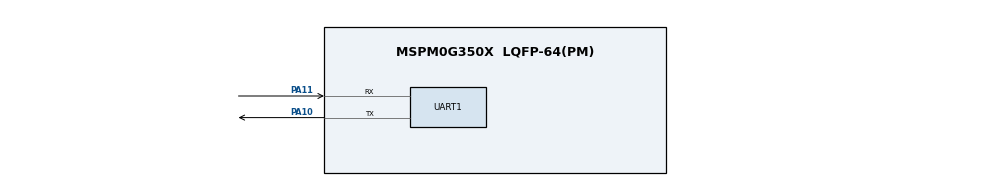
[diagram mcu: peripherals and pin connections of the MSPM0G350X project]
// @cliArgs --device "MSPM0G350X" --package "LQFP-64(PM)" --part "Default"
// @cliArgs --board /ti/boards/LP_MSPM0G3507 --rtos nortos

/**
 * Import the modules used in this configuration.
 */
const UART   = scripting.addModule("/ti/driverlib/UART", {}, false);
const UART1  = UART.addInstance();

const GPIO   = scripting.addModule("/ti/driverlib/GPIO", {}, false);
const GPIO1  = GPIO.addInstance();

const SYSCTL = scripting.addModule("/ti/driverlib/SYSCTL");

/**
 * Write custom configuration values to the imported modules.
 */

UART1.$name = "UART_0";
UART1.profile = "CONFIG_PROFILE_1";
UART1.peripheral.$assign = "UART0";
UART1.targetBaudRate = 9600;
UART1.enableInternalLoopback = false;
UART1.enableFIFO = true;
UART1.rxFifoThreshold = "DL_UART_RX_FIFO_LEVEL_1_2_FULL";

UART1.peripheral.rxPin.$assign = "PA11";
UART1.peripheral.txPin.$assign = "PA10";

GPIO1.$name                          = "GPIO_LEDS";
GPIO1.associatedPins[0].$name        = "USER_LED_1";
GPIO1.associatedPins[0].assignedPort = "PORTA";
GPIO1.associatedPins[0].assignedPin  = "0";
GPIO1.associatedPins[0].initialValue = "SET";

SYSCTL.clockTreeEn = true;
